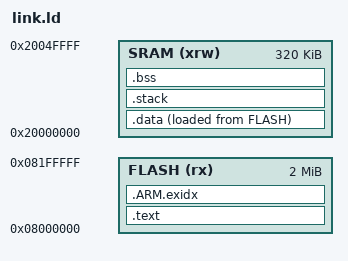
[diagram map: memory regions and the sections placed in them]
/* Linker script for GD32W51x_F5HC with GNU LD */
/* Memory Spaces Definitions */
MEMORY
{
  FLASH (rx)  : ORIGIN = 0x08000000, LENGTH = 2048K
  SRAM  (xrw) : ORIGIN = 0x20000000, LENGTH = 320K
}

ENTRY(Reset_Handler)
_system_stack_size = 0x400;

SECTIONS
{
    .text :
    {
        . = ALIGN(4);
        _stext = .;
        KEEP(*(.isr_vector))
        KEEP(*(.vectors))
        *(.text)
        *(.text.*)
        *(.rodata)
        *(.rodata*)
        *(.glue_7)
        *(.glue_7t)
        *(.gnu.linkonce.t*)

        /* section information for finsh shell */
        . = ALIGN(4);
        __fsymtab_start = .;
        KEEP(*(FSymTab))
        __fsymtab_end = .;
        . = ALIGN(4);
        __vsymtab_start = .;
        KEEP(*(VSymTab))
        __vsymtab_end = .;
        . = ALIGN(4);

        /* section information for initial. */
        . = ALIGN(4);
        __rt_init_start = .;
        KEEP(*(SORT(.rti_fn*)))
        __rt_init_end = .;

        
        
        . = ALIGN(4);

        KEEP(*(.init))
        KEEP(*(.fini))

        . = ALIGN(4);
        _etext = .;
    } > FLASH

    /* .ARM.exidx is sorted, so has to go in its own output section.  */
    __exidx_start = .;
    .ARM.exidx :
    {
        *(.ARM.exidx* .gnu.linkonce.armexidx.*)
    } > FLASH
    __exidx_end = .;

    /* Used by the startup to initialize data */
    _sidata = LOADADDR(.data);

    .data :
    {
        . = ALIGN(4);
        _sdata = .;
        *(.data)
        *(.data.*)
        *(.gnu.linkonce.d*)

        . = ALIGN(4);
        _edata = .;
    } >SRAM AT>FLASH

    .stack :
    {
        . = ALIGN(4);
        _sstack = .;
        . = . + _system_stack_size;
        . = ALIGN(4);
        _estack = .;
    } >SRAM

    __bss_start = .;
    .bss :
    {
        . = ALIGN(4);
        _sbss = .;
        *(.bss)
        *(.bss.*)
        *(COMMON)
        . = ALIGN(4);
        _ebss = .;
    } >SRAM
    __bss_end = .;
    _end = .;

    /* Top of stack - used by startup as initial SP */
    _sp = ORIGIN(SRAM) + LENGTH(SRAM);

    /* Stabs debugging sections.  */
    .stab          0 : { *(.stab) }
    .stabstr       0 : { *(.stabstr) }
    .stab.excl     0 : { *(.stab.excl) }
    .stab.exclstr  0 : { *(.stab.exclstr) }
    .stab.index    0 : { *(.stab.index) }
    .stab.indexstr 0 : { *(.stab.indexstr) }
    .comment       0 : { *(.comment) }
}
